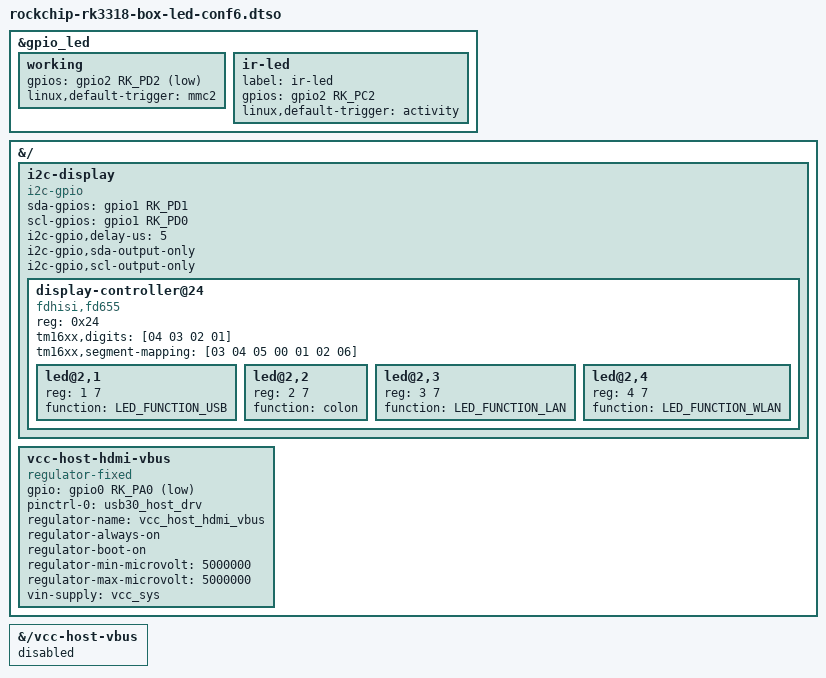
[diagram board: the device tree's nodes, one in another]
/dts-v1/;
/plugin/;

#include <dt-bindings/gpio/gpio.h>
#include <dt-bindings/leds/common.h>
#include <dt-bindings/pinctrl/rockchip.h>

/**
 * T98_RK3318 (Hongtop H50)
 */

&gpio_led {

	working {
		gpios = <&gpio2 RK_PD2 GPIO_ACTIVE_LOW>;
		linux,default-trigger = "mmc2";
	};
        ir-led {
                label = "ir-led";
                gpios = <&gpio2 RK_PC2 GPIO_ACTIVE_HIGH>;
                linux,default-trigger = "activity";
            };
};

&{/} {

	i2c-display {
		compatible = "i2c-gpio";
		sda-gpios = <&gpio1 RK_PD1 (GPIO_ACTIVE_HIGH|GPIO_OPEN_DRAIN)>;
		scl-gpios = <&gpio1 RK_PD0 (GPIO_ACTIVE_HIGH|GPIO_OPEN_DRAIN)>;
		i2c-gpio,delay-us = <5>;
		i2c-gpio,sda-output-only;
		i2c-gpio,scl-output-only;
		#address-cells = <1>;
		#size-cells = <0>;

		display-controller@24 {
			#address-cells = <2>;
			#size-cells = <0>;

			compatible = "fdhisi,fd655"; /* fd650 not able to set segment 8 (07) for function leds */
			reg = <0x24>;
			tm16xx,digits = [04 03 02 01];
			tm16xx,segment-mapping = [03 04 05 00 01 02 06];

			led@2,1 {
				reg = <1 7>;
				function = LED_FUNCTION_USB;
			};

			led@2,2 {
				reg = <2 7>;
				function = "colon";
			};

			led@2,3 {
				reg = <3 7>;
				function = LED_FUNCTION_LAN;
			};

			led@2,4 {
				reg = <4 7>;
				function = LED_FUNCTION_WLAN;
			};

		};

	};

};

/* modify existimg regulator to power on HDMI */

&{/vcc-host-vbus} {
    status = "disabled";
};
&{/} {
	vcc-host-hdmi-vbus {
	        compatible = "regulator-fixed";
	        gpio = <&gpio0 RK_PA0 GPIO_ACTIVE_LOW>;
	        pinctrl-names = "default";
	        pinctrl-0 = <&usb30_host_drv>;
	        regulator-name = "vcc_host_hdmi_vbus";
	        regulator-always-on;
	        regulator-boot-on;
	        regulator-min-microvolt = <5000000>;
	        regulator-max-microvolt = <5000000>;
	        vin-supply = <&vcc_sys>;
   	 };

   };


